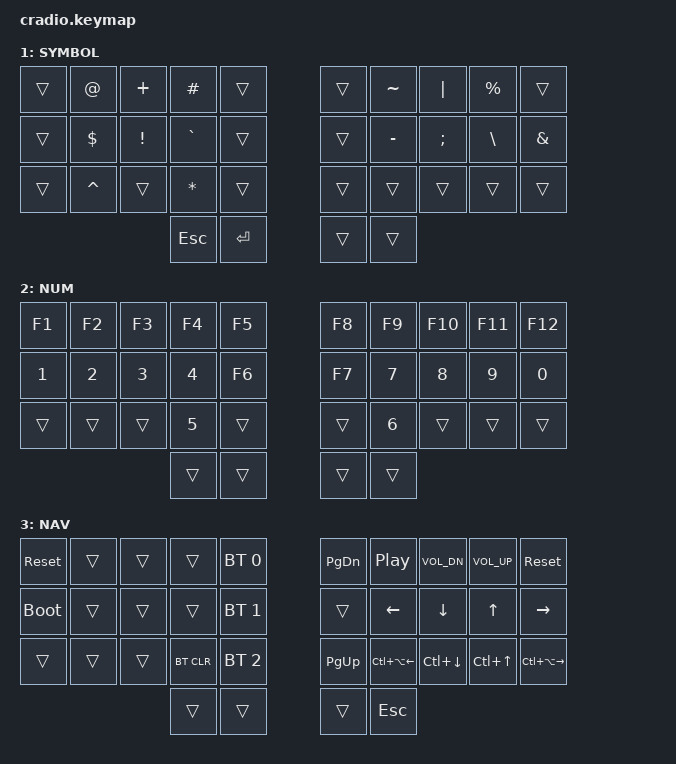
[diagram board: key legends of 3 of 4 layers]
// Copyright (c) 2022 The ZMK Contributors
// SPDX-License-Identifier: MIT

#include <behaviors.dtsi>
#include <dt-bindings/zmk/keys.h>
#include <dt-bindings/zmk/bt.h>

// Home row mods macro
#define HRML(k1,k2,k3) &ht LALT k1  &ht LCTRL k2  &ht LSHFT k3
#define HRMR(k1,k2,k3) &ht RSHFT k1  &ht RCTRL k2  &ht RALT k3

#define DEFAULT 0
#define SYMBOL  1
#define NUM     2
#define NAV     3

// Combo macros
#define COMBO(NAME, BINDINGS, KEYPOS) \
  combo_##NAME { \
    timeout-ms = <50>; \
    bindings = <BINDINGS>; \
    key-positions = <KEYPOS>; \
    layers = <DEFAULT>; \
  };

/ {
    behaviors {
        ht: hold_tap {
            compatible = "zmk,behavior-hold-tap";
            #binding-cells = <2>;
            flavor = "tap-preferred";
            tapping-term-ms = <220>;
            quick-tap-ms = <150>;
            require-prior-idle-ms = <100>;
            bindings = <&kp>, <&kp>;
        };
    };

    combos {
        compatible = "zmk,combos";
        COMBO(enter, &kp ENTER, 31 32)
        COMBO(lbrc, &kp LBRC, 11 12)
        COMBO(rbrc, &kp RBRC, 17 18)
        COMBO(lpar, &kp LPAR, 12 13)
        COMBO(rpar, &kp RPAR, 16 17)
        COMBO(lbkt, &kp LBKT, 2 3)
        COMBO(rbkt, &kp RBKT, 6 7)
        COMBO(colon, &kp COLON, 11 13)
        COMBO(equal, &kp EQUAL, 16 18)
        COMBO(unds, &kp UNDER, 13 16)
        COMBO(caps_word, &caps_word, 3 6)
    };

    keymap {
        compatible = "zmk,keymap";
        DEFAULT {
            bindings = <
            &kp Q      &kp W      &kp F      &kp P              &kp B          &kp J      &kp L            &kp U      &kp Y      &kp SQT  
            &kp A      HRML(R,    S,         T)                 &kp G          &kp M      HRMR(N,          E,         I)         &kp O
            &kp Z      &kp X      &kp C     &ht LCMD D          &kp V          &kp K      &ht RCMD H       &kp COMMA  &kp DOT    &kp FSLH
                                            &lt NUM SPACE       &lt NAV TAB    &kp BSPC   &sl SYMBOL
            >;
        };

        SYMBOL {
            bindings = <
            &trans     &kp AT     &kp PLUS   &kp HASH   &trans         &trans     &kp TILDE  &kp PIPE   &kp PRCNT  &trans 
            &trans     &kp DLLR   &kp EXCL   &kp GRAVE  &trans         &trans     &kp MINUS  &kp SEMI   &kp BSLH   &kp AMPS
            &trans     &kp CARET  &trans     &kp ASTRK  &trans         &trans     &trans     &trans     &trans     &trans
                                             &kp ESC    &kp ENTER      &trans     &trans
            >;
        };

        NUM {
            bindings = <
            &kp F1    &kp F2     &kp F3     &kp F4     &kp F5         &kp F8    &kp F9     &kp F10    &kp F11    &kp F12
            &kp N1    &kp N2     &kp N3     &kp N4     &kp F6         &kp F7    &kp N7     &kp N8     &kp N9     &kp N0
            &trans    &trans     &trans     &kp N5     &trans         &trans    &kp N6     &trans     &trans     &trans
                                            &trans     &trans         &trans    &trans
            >;
        };

        NAV {
            bindings = <
            &sys_reset   &trans     &trans     &trans     &bt BT_SEL 0    &kp PG_DN  &kp C_PP           &kp C_VOL_DN   &kp C_VOL_UP   &sys_reset
            &bootloader  &trans     &trans     &trans     &bt BT_SEL 1    &trans     &kp LEFT           &kp DOWN       &kp UP         &kp RIGHT
            &trans       &trans     &trans     &bt BT_CLR &bt BT_SEL 2    &kp PG_UP  &kp LC(LA(LEFT))   &kp LC(DOWN)   &kp LC(UP)     &kp LC(LA(RIGHT))
                                               &trans     &trans          &trans     &kp ESC
            >;
        };
    };
};
